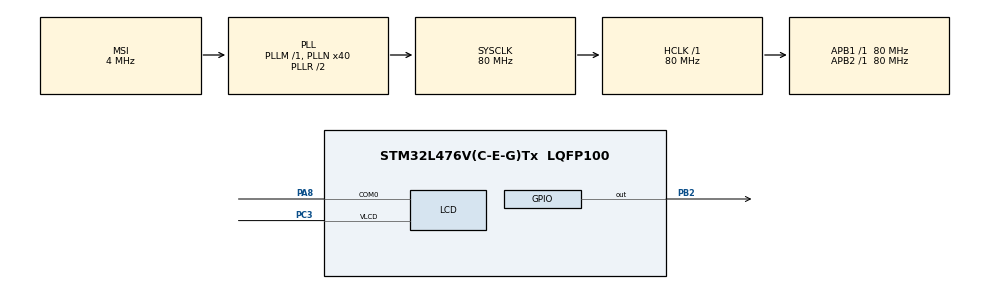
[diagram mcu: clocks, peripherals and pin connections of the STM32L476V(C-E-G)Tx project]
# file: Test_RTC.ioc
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Mcu.Family=STM32L4
Mcu.Name=STM32L476V(C-E-G)Tx
Mcu.Package=LQFP100
NVIC.PriorityGroup=NVIC_PRIORITYGROUP_4
PA8.Mode=Static
PA8.Signal=LCD_COM0
PB2.Signal=GPIO_Output
PC14/OSC32_IN.Mode=LSE-External-Oscillator
PC14/OSC32_IN.Signal=RCC_OSC32_IN
PC15/OSC32_OUT.Mode=LSE-External-Oscillator
PC15/OSC32_OUT.Signal=RCC_OSC32_OUT
PC3.Mode=Static
PC3.Signal=LCD_VLCD
ProjectManager.HeapSize=0x200
ProjectManager.StackSize=0x400
ProjectManager.TargetToolchain=MDK-ARM V5
RCC.AHBFreq_Value=80000000
RCC.APB1Freq_Value=80000000
RCC.APB1TimFreq_Value=80000000
RCC.APB2Freq_Value=80000000
RCC.APB2TimFreq_Value=80000000
RCC.CortexFreq_Value=80000000
RCC.HCLKFreq_Value=80000000
RCC.HSE_VALUE=8000000
RCC.HSI_VALUE=16000000
RCC.MSI_VALUE=4000000
RCC.PLLN=40
RCC.RTCClockSelection=RCC_RTCCLKSOURCE_LSE
RCC.SYSCLKFreq_VALUE=80000000
RCC.SYSCLKSource=RCC_SYSCLKSOURCE_PLLCLK
RCC.VCOOutputFreq_Value=160000000
RTC.Date=10
RTC.Hours=21
RTC.Hours_A-Alarm\ A=22
RTC.Minutes=12
RTC.Minutes_A-Alarm\ A=44
RTC.Month=RTC_MONTH_OCTOBER
RTC.Seconds=52
RTC.Seconds_A-Alarm\ A=10
RTC.Year=16
VP_RTC_VS_RTC_Alarm_A_Intern.Mode=Alarm A
board=Test_RTC

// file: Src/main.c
/**
  ******************************************************************************
  * File Name          : main.c
  * Description        : Main program body
  ******************************************************************************
  *
  * COPYRIGHT(c) 2016 STMicroelectronics
  *
  * Redistribution and use in source and binary forms, with or without modification,
  * are permitted provided that the following conditions are met:
  *   1. Redistributions of source code must retain the above copyright notice,
  *      this list of conditions and the following disclaimer.
  *   2. Redistributions in binary form must reproduce the above copyright notice,
  *      this list of conditions and the following disclaimer in the documentation
  *      and/or other materials provided with the distribution.
  *   3. Neither the name of STMicroelectronics nor the names of its contributors
  *      may be used to endorse or promote products derived from this software
  *      without specific prior written permission.
  *
  * THIS SOFTWARE IS PROVIDED BY THE COPYRIGHT HOLDERS AND CONTRIBUTORS "AS IS"
  * AND ANY EXPRESS OR IMPLIED WARRANTIES, INCLUDING, BUT NOT LIMITED TO, THE
  * IMPLIED WARRANTIES OF MERCHANTABILITY AND FITNESS FOR A PARTICULAR PURPOSE ARE
  * DISCLAIMED. IN NO EVENT SHALL THE COPYRIGHT HOLDER OR CONTRIBUTORS BE LIABLE
  * FOR ANY DIRECT, INDIRECT, INCIDENTAL, SPECIAL, EXEMPLARY, OR CONSEQUENTIAL
  * DAMAGES (INCLUDING, BUT NOT LIMITED TO, PROCUREMENT OF SUBSTITUTE GOODS OR
  * SERVICES; LOSS OF USE, DATA, OR PROFITS; OR BUSINESS INTERRUPTION) HOWEVER
  * CAUSED AND ON ANY THEORY OF LIABILITY, WHETHER IN CONTRACT, STRICT LIABILITY,
  * OR TORT (INCLUDING NEGLIGENCE OR OTHERWISE) ARISING IN ANY WAY OUT OF THE USE
  * OF THIS SOFTWARE, EVEN IF ADVISED OF THE POSSIBILITY OF SUCH DAMAGE.
  *
  ******************************************************************************
  */
#include "stm32l4xx_hal.h"

/* USER CODE BEGIN Includes */
#include "stm32l476g_discovery_glass_lcd.h"
/* USER CODE END Includes */

LCD_HandleTypeDef hlcd;

RTC_HandleTypeDef hrtc;

/* USER CODE BEGIN PV */
/* Private variables ---------------------------------------------------------*/

/* USER CODE END PV */

void SystemClock_Config(void);
void Error_Handler(void);
static void MX_GPIO_Init(void);
static void MX_RTC_Init(void);
static void MX_LCD_Init(void);

/* USER CODE BEGIN PFP */
/* Private function prototypes -----------------------------------------------*/
void ConvertU8toU16(char* str, uint16_t *buf);
/* USER CODE END PFP */

/* USER CODE BEGIN 0 */
  RTC_TimeTypeDef sTime;
  RTC_DateTypeDef sDate;
/* USER CODE END 0 */

int main(void)
{

  /* MCU Configuration----------------------------------------------------------*/

  /* Reset of all peripherals, Initializes the Flash interface and the Systick. */
  HAL_Init();

  /* Configure the system clock */
  SystemClock_Config();

  /* Initialize all configured peripherals */
  MX_GPIO_Init();
  MX_RTC_Init();
  //MX_LCD_Init();

  /* Infinite loop */
  /* USER CODE BEGIN WHILE */
	BSP_LCD_GLASS_Init();
	char str[6]="Hello";
	uint16_t str16[6];
	BSP_LCD_GLASS_DisplayString((uint8_t*)str);
  while (1)
  {
		BSP_LCD_GLASS_Clear();
		ConvertU8toU16(str,str16);
		BSP_LCD_GLASS_DisplayStrDeci(str16);
		//HT HU MNT MNU ST SU
		//hrtc.Init.
		HAL_RTC_GetTime(&hrtc, &sTime, RTC_FORMAT_BIN);
		sprintf(str,"%2d:%2d",sTime.Minutes,sTime.Seconds);
		//HAL_Delay(1000);
		HAL_GPIO_TogglePin(GPIOB,GPIO_PIN_2);
  /* USER CODE END WHILE */

  }

}

/** System Clock Configuration
*/
void SystemClock_Config(void)
{

  RCC_OscInitTypeDef RCC_OscInitStruct;
  RCC_ClkInitTypeDef RCC_ClkInitStruct;
  RCC_PeriphCLKInitTypeDef PeriphClkInit;

  RCC_OscInitStruct.OscillatorType = RCC_OSCILLATORTYPE_LSE|RCC_OSCILLATORTYPE_MSI;
  RCC_OscInitStruct.LSEState = RCC_LSE_ON;
  RCC_OscInitStruct.MSIState = RCC_MSI_ON;
  RCC_OscInitStruct.MSICalibrationValue = 0;
  RCC_OscInitStruct.MSIClockRange = RCC_MSIRANGE_6;
  RCC_OscInitStruct.PLL.PLLState = RCC_PLL_ON;
  RCC_OscInitStruct.PLL.PLLSource = RCC_PLLSOURCE_MSI;
  RCC_OscInitStruct.PLL.PLLM = 1;
  RCC_OscInitStruct.PLL.PLLN = 40;
  RCC_OscInitStruct.PLL.PLLP = RCC_PLLP_DIV7;
  RCC_OscInitStruct.PLL.PLLQ = RCC_PLLQ_DIV2;
  RCC_OscInitStruct.PLL.PLLR = RCC_PLLR_DIV2;
  if (HAL_RCC_OscConfig(&RCC_OscInitStruct) != HAL_OK)
  {
    Error_Handler();
  }

  RCC_ClkInitStruct.ClockType = RCC_CLOCKTYPE_HCLK|RCC_CLOCKTYPE_SYSCLK
                              |RCC_CLOCKTYPE_PCLK1|RCC_CLOCKTYPE_PCLK2;
  RCC_ClkInitStruct.SYSCLKSource = RCC_SYSCLKSOURCE_PLLCLK;
  RCC_ClkInitStruct.AHBCLKDivider = RCC_SYSCLK_DIV1;
  RCC_ClkInitStruct.APB1CLKDivider = RCC_HCLK_DIV1;
  RCC_ClkInitStruct.APB2CLKDivider = RCC_HCLK_DIV1;
  if (HAL_RCC_ClockConfig(&RCC_ClkInitStruct, FLASH_LATENCY_4) != HAL_OK)
  {
    Error_Handler();
  }

  PeriphClkInit.PeriphClockSelection = RCC_PERIPHCLK_RTC;
  PeriphClkInit.RTCClockSelection = RCC_RTCCLKSOURCE_LSE;
  if (HAL_RCCEx_PeriphCLKConfig(&PeriphClkInit) != HAL_OK)
  {
    Error_Handler();
  }

  __HAL_RCC_PWR_CLK_ENABLE();

  if (HAL_PWREx_ControlVoltageScaling(PWR_REGULATOR_VOLTAGE_SCALE1) != HAL_OK)
  {
    Error_Handler();
  }

  HAL_SYSTICK_Config(HAL_RCC_GetHCLKFreq()/1000);

  HAL_SYSTICK_CLKSourceConfig(SYSTICK_CLKSOURCE_HCLK);

  /* SysTick_IRQn interrupt configuration */
  HAL_NVIC_SetPriority(SysTick_IRQn, 0, 0);
}

/* LCD init function */
static void MX_LCD_Init(void)
{

  hlcd.Instance = LCD;
  hlcd.Init.Prescaler = LCD_PRESCALER_1;
  hlcd.Init.Divider = LCD_DIVIDER_16;
  hlcd.Init.Duty = LCD_DUTY_STATIC;
  hlcd.Init.Bias = LCD_BIAS_1_4;
  hlcd.Init.VoltageSource = LCD_VOLTAGESOURCE_INTERNAL;
  hlcd.Init.Contrast = LCD_CONTRASTLEVEL_0;
  hlcd.Init.DeadTime = LCD_DEADTIME_0;
  hlcd.Init.PulseOnDuration = LCD_PULSEONDURATION_0;
  hlcd.Init.MuxSegment = LCD_MUXSEGMENT_DISABLE;
  hlcd.Init.BlinkMode = LCD_BLINKMODE_OFF;
  hlcd.Init.BlinkFrequency = LCD_BLINKFREQUENCY_DIV8;
  hlcd.Init.HighDrive = LCD_HIGHDRIVE_DISABLE;
  if (HAL_LCD_Init(&hlcd) != HAL_OK)
  {
    Error_Handler();
  }

}

/* RTC init function */
static void MX_RTC_Init(void)
{

  RTC_AlarmTypeDef sAlarm;

    /**Initialize RTC and set the Time and Date
    */
  hrtc.Instance = RTC;
  hrtc.Init.HourFormat = RTC_HOURFORMAT_24;
  hrtc.Init.AsynchPrediv = 127;
  hrtc.Init.SynchPrediv = 255;
  hrtc.Init.OutPut = RTC_OUTPUT_DISABLE;
  hrtc.Init.OutPutRemap = RTC_OUTPUT_REMAP_NONE;
  hrtc.Init.OutPutPolarity = RTC_OUTPUT_POLARITY_HIGH;
  hrtc.Init.OutPutType = RTC_OUTPUT_TYPE_OPENDRAIN;
  if (HAL_RTC_Init(&hrtc) != HAL_OK)
  {
    Error_Handler();
  }

  sTime.Hours = 0x21;
  sTime.Minutes = 0x12;
  sTime.Seconds = 0x52;
  sTime.DayLightSaving = RTC_DAYLIGHTSAVING_NONE;
  sTime.StoreOperation = RTC_STOREOPERATION_RESET;
  if (HAL_RTC_SetTime(&hrtc, &sTime, RTC_FORMAT_BCD) != HAL_OK)
  {
    Error_Handler();
  }

  sDate.WeekDay = RTC_WEEKDAY_MONDAY;
  sDate.Month = RTC_MONTH_OCTOBER;
  sDate.Date = 0x10;
  sDate.Year = 0x16;

  if (HAL_RTC_SetDate(&hrtc, &sDate, RTC_FORMAT_BCD) != HAL_OK)
  {
    Error_Handler();
  }

    /**Enable the Alarm A
    */
	/*
  sAlarm.AlarmTime.Hours = 0x22;
  sAlarm.AlarmTime.Minutes = 0x44;
  sAlarm.AlarmTime.Seconds = 0x10;
  sAlarm.AlarmTime.SubSeconds = 0x0;
  sAlarm.AlarmTime.DayLightSaving = RTC_DAYLIGHTSAVING_NONE;
  sAlarm.AlarmTime.StoreOperation = RTC_STOREOPERATION_RESET;
  sAlarm.AlarmMask = RTC_ALARMMASK_NONE;
  sAlarm.AlarmSubSecondMask = RTC_ALARMSUBSECONDMASK_ALL;
  sAlarm.AlarmDateWeekDaySel = RTC_ALARMDATEWEEKDAYSEL_DATE;
  sAlarm.AlarmDateWeekDay = 0x1;
  sAlarm.Alarm = RTC_ALARM_A;
  if (HAL_RTC_SetAlarm(&hrtc, &sAlarm, RTC_FORMAT_BCD) != HAL_OK)
  {
    Error_Handler();
  }
*/
}

/** Configure pins as
        * Analog
        * Input
        * Output
        * EVENT_OUT
        * EXTI
*/
static void MX_GPIO_Init(void)
{

  GPIO_InitTypeDef GPIO_InitStruct;

  /* GPIO Ports Clock Enable */
  __HAL_RCC_GPIOC_CLK_ENABLE();
  __HAL_RCC_GPIOB_CLK_ENABLE();
  __HAL_RCC_GPIOA_CLK_ENABLE();

  /*Configure GPIO pin Output Level */
  HAL_GPIO_WritePin(GPIOB, GPIO_PIN_2, GPIO_PIN_RESET);

  /*Configure GPIO pin : PB2 */
  GPIO_InitStruct.Pin = GPIO_PIN_2;
  GPIO_InitStruct.Mode = GPIO_MODE_OUTPUT_PP;
  GPIO_InitStruct.Pull = GPIO_NOPULL;
  GPIO_InitStruct.Speed = GPIO_SPEED_FREQ_LOW;
  HAL_GPIO_Init(GPIOB, &GPIO_InitStruct);

}

/* USER CODE BEGIN 4 */
void ConvertU8toU16(char* str, uint16_t *buf)
{
	int size = sizeof(str);
	for(int i = 0; i < size+1; i++)
	{
		buf[i] = (uint16_t)str[i];
	}
}
/* USER CODE END 4 */

void Error_Handler(void)
{
  while(1)
  {
  }
}

/************************ (C) COPYRIGHT STMicroelectronics *****END OF FILE****/
